VERSION "_"

NS_ :

BS_:

BU_: bms_lv dash dspace sens_front sens_rear tlb_bat

BO_ 20 BMSLV_Helo : 8 bms_lv
	SG_ time : 0|64@1+ (1,0) [0|18446744073709552000] "" dspace

BO_ 21 Sens_Front_Helo : 8 bms_lv
	SG_ time : 0|64@1+ (1,0) [0|18446744073709552000] "" dspace

BO_ 22 Sens_Rear_Helo : 8 bms_lv
	SG_ time : 0|64@1+ (1,0) [0|18446744073709552000] "" dspace

BO_ 23 Steering_Helo : 8 bms_lv
	SG_ time : 0|64@1+ (1,0) [0|18446744073709552000] "" dspace

BO_ 24 TLB_Battery_Helo : 8 bms_lv
	SG_ time : 0|64@1+ (1,0) [0|18446744073709552000] "" dspace

BO_ 25 dSpaxe_Helo : 8 bms_lv
	SG_ time : 0|64@1+ (1,0) [0|18446744073709552000] "" dspace

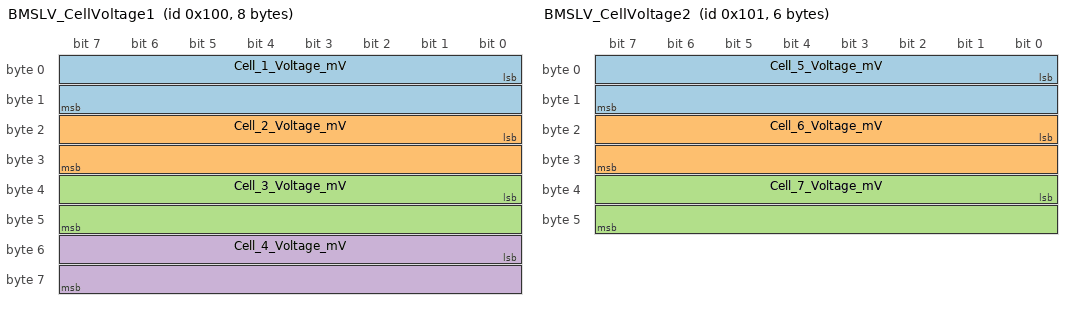
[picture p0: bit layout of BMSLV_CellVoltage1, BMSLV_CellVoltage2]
BO_ 256 BMSLV_CellVoltage1 : 8 bms_lv
	SG_ Cell_1_Voltage_mV : 0|16@1+ (0.038,2000) [0|2490.33] "" dspace
	SG_ Cell_2_Voltage_mV : 16|16@1+ (0.038,2000) [0|2490.33] "" dspace
	SG_ Cell_3_Voltage_mV : 32|16@1+ (0.038,2000) [0|2490.33] "" dspace
	SG_ Cell_4_Voltage_mV : 48|16@1+ (0.038,2000) [0|2490.33] "" dspace

BO_ 257 BMSLV_CellVoltage2 : 6 bms_lv
	SG_ Cell_5_Voltage_mV : 0|16@1+ (0.038,2000) [0|2490.33] "" dspace
	SG_ Cell_6_Voltage_mV : 16|16@1+ (0.038,2000) [0|2490.33] "" dspace
	SG_ Cell_7_Voltage_mV : 32|16@1+ (0.038,2000) [0|2490.33] "" dspace

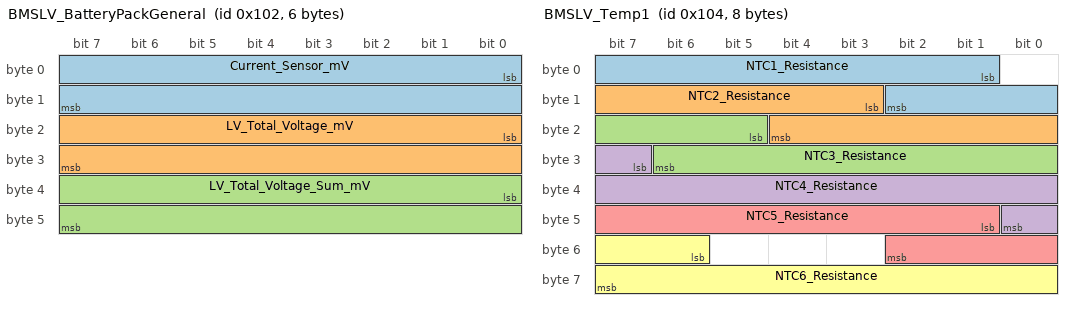
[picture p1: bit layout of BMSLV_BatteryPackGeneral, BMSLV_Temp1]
BO_ 258 BMSLV_BatteryPackGeneral : 6 bms_lv
	SG_ Current_Sensor_mV : 0|16@1+ (0.076,0) [0|4980.66] "" dspace
	SG_ LV_Total_Voltage_mV : 16|16@1+ (0.267,14000) [0|17497.845] "" dspace
	SG_ LV_Total_Voltage_Sum_mV : 32|16@1+ (0.267,14000) [0|17497.845] "" dspace

BO_ 259 BMSLV_Status : 4 bms_lv
	SG_ isRelayOpen : 0|1@1+ (1,0) [0|1] "" dspace
	SG_ cell1_OV : 1|1@1+ (1,0) [0|1] "" dspace
	SG_ cell2_OV : 2|1@1+ (1,0) [0|1] "" dspace
	SG_ cell3_OV : 3|1@1+ (1,0) [0|1] "" dspace
	SG_ cell4_OV : 4|1@1+ (1,0) [0|1] "" dspace
	SG_ cell5_OV : 5|1@1+ (1,0) [0|1] "" dspace
	SG_ cell6_OV : 6|1@1+ (1,0) [0|1] "" dspace
	SG_ cell7_OV : 7|1@1+ (1,0) [0|1] "" dspace
	SG_ cell1_UV : 8|1@1+ (1,0) [0|1] "" dspace
	SG_ cell2_UV : 9|1@1+ (1,0) [0|1] "" dspace
	SG_ cell3_UV : 10|1@1+ (1,0) [0|1] "" dspace
	SG_ cell4_UV : 11|1@1+ (1,0) [0|1] "" dspace
	SG_ cell5_UV : 12|1@1+ (1,0) [0|1] "" dspace
	SG_ cell6_UV : 13|1@1+ (1,0) [0|1] "" dspace
	SG_ cell7_UV : 14|1@1+ (1,0) [0|1] "" dspace
	SG_ temp1_OT : 15|1@1+ (1,0) [0|1] "" dspace
	SG_ temp2_OT : 16|1@1+ (1,0) [0|1] "" dspace
	SG_ temp3_OT : 17|1@1+ (1,0) [0|1] "" dspace
	SG_ temp4_OT : 18|1@1+ (1,0) [0|1] "" dspace
	SG_ temp5_OT : 19|1@1+ (1,0) [0|1] "" dspace
	SG_ temp6_OT : 20|1@1+ (1,0) [0|1] "" dspace
	SG_ temp7_OT : 21|1@1+ (1,0) [0|1] "" dspace
	SG_ temp8_OT : 22|1@1+ (1,0) [0|1] "" dspace
	SG_ temp9_OT : 23|1@1+ (1,0) [0|1] "" dspace
	SG_ temp10_OT : 24|1@1+ (1,0) [0|1] "" dspace
	SG_ temp11_OT : 25|1@1+ (1,0) [0|1] "" dspace
	SG_ temp12_OT : 26|1@1+ (1,0) [0|1] "" dspace

BO_ 260 BMSLV_Temp1 : 8 bms_lv
	SG_ NTC1_Resistance : 1|10@1+ (31.25,1000) [0|31968.75] "Ohm" dspace
	SG_ NTC2_Resistance : 11|10@1+ (31.25,1000) [0|31968.75] "Ohm" dspace
	SG_ NTC3_Resistance : 21|10@1+ (31.25,1000) [0|31968.75] "Ohm" dspace
	SG_ NTC4_Resistance : 31|10@1+ (31.25,1000) [0|31968.75] "Ohm" dspace
	SG_ NTC5_Resistance : 41|10@1+ (31.25,1000) [0|31968.75] "Ohm" dspace
	SG_ NTC6_Resistance : 54|10@1+ (31.25,1000) [0|31968.75] "Ohm" dspace

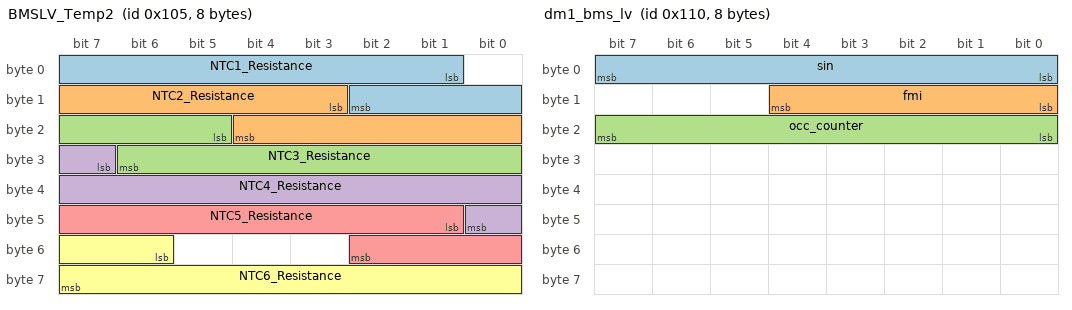
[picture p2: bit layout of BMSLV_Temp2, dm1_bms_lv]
BO_ 261 BMSLV_Temp2 : 8 bms_lv
	SG_ NTC1_Resistance : 1|10@1+ (31.25,1000) [0|31968.75] "Ohm" dspace
	SG_ NTC2_Resistance : 11|10@1+ (31.25,1000) [0|31968.75] "Ohm" dspace
	SG_ NTC3_Resistance : 21|10@1+ (31.25,1000) [0|31968.75] "Ohm" dspace
	SG_ NTC4_Resistance : 31|10@1+ (31.25,1000) [0|31968.75] "Ohm" dspace
	SG_ NTC5_Resistance : 41|10@1+ (31.25,1000) [0|31968.75] "Ohm" dspace
	SG_ NTC6_Resistance : 54|10@1+ (31.25,1000) [0|31968.75] "Ohm" dspace

BO_ 272 dm1_bms_lv : 8 bms_lv
	SG_ sin : 0|8@1+ (1,0) [0|117] "" Vector__XXX
	SG_ fmi : 8|5@1+ (1,0) [0|31] "" Vector__XXX
	SG_ occ_counter : 16|8@1+ (1,0) [0|255] "" Vector__XXX

BO_ 38 Steering_RTD : 1 dash
	SG_ RTD_CMD : 0|8@1+ (1,0) [0|255] "" dspace

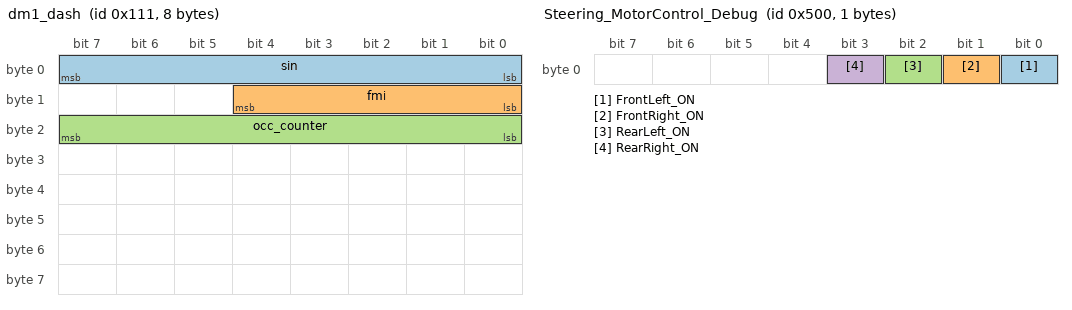
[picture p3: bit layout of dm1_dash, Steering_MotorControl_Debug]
BO_ 273 dm1_dash : 8 dash
	SG_ sin : 0|8@1+ (1,0) [0|117] "" Vector__XXX
	SG_ fmi : 8|5@1+ (1,0) [0|31] "" Vector__XXX
	SG_ occ_counter : 16|8@1+ (1,0) [0|255] "" Vector__XXX

BO_ 1280 Steering_MotorControl_Debug : 1 dash
	SG_ FrontLeft_ON : 0|1@1- (1,0) [0|1] "" dspace
	SG_ FrontRight_ON : 1|1@1- (1,0) [0|1] "" dspace
	SG_ RearLeft_ON : 2|1@1- (1,0) [0|1] "" dspace
	SG_ RearRight_ON : 3|1@1- (1,0) [0|1] "" dspace

BO_ 37 dSpace_RTD_ACK : 1 dspace
	SG_ RTD_FSM_STATE : 0|8@1- (1,0) [-1|6] "" dash

BO_ 255 BMSLV_RelayOverride : 2 dspace
	SG_ password : 0|15@1+ (1,0) [0|65535] "" bms_lv
	SG_ close_relay : 15|1@1+ (1,0) [0|1] "" bms_lv

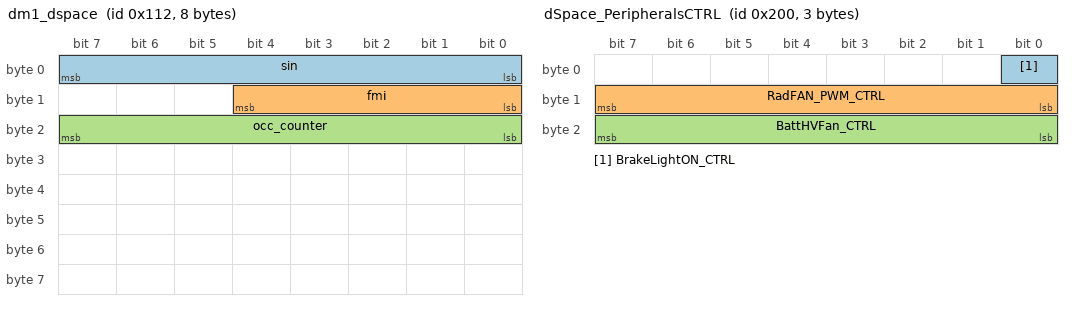
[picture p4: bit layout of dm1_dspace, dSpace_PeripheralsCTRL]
BO_ 274 dm1_dspace : 8 dspace
	SG_ sin : 0|8@1+ (1,0) [0|117] "" Vector__XXX
	SG_ fmi : 8|5@1+ (1,0) [0|31] "" Vector__XXX
	SG_ occ_counter : 16|8@1+ (1,0) [0|255] "" Vector__XXX

BO_ 512 dSpace_PeripheralsCTRL : 3 dspace
	SG_ BrakeLightON_CTRL : 0|1@1- (1,0) [0|1] "" dash
	SG_ RadFAN_PWM_CTRL : 8|8@1+ (1,0) [0|255] "" dash
	SG_ BattHVFan_CTRL : 16|8@1+ (1,0) [0|255] "" dash

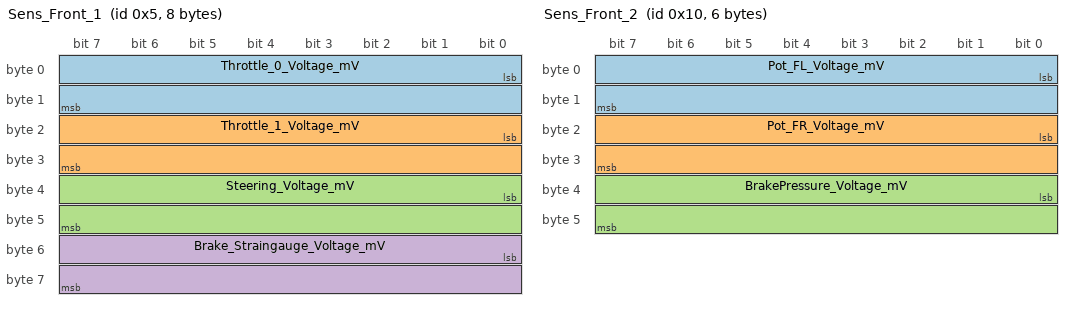
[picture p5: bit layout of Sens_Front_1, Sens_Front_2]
BO_ 5 Sens_Front_1 : 8 sens_front
	SG_ Throttle_0_Voltage_mV : 0|16@1+ (1,0) [0|65535] "" dspace
	SG_ Throttle_1_Voltage_mV : 16|16@1+ (1,0) [0|65535] "" dspace
	SG_ Steering_Voltage_mV : 32|16@1+ (1,0) [0|65535] "" dspace
	SG_ Brake_Straingauge_Voltage_mV : 48|16@1+ (1,0) [0|65535] "" dspace

BO_ 16 Sens_Front_2 : 6 sens_front
	SG_ Pot_FL_Voltage_mV : 0|16@1+ (1,0) [0|65535] "" dspace
	SG_ Pot_FR_Voltage_mV : 16|16@1+ (1,0) [0|65535] "" dspace
	SG_ BrakePressure_Voltage_mV : 32|16@1+ (1,0) [0|65535] "" dspace

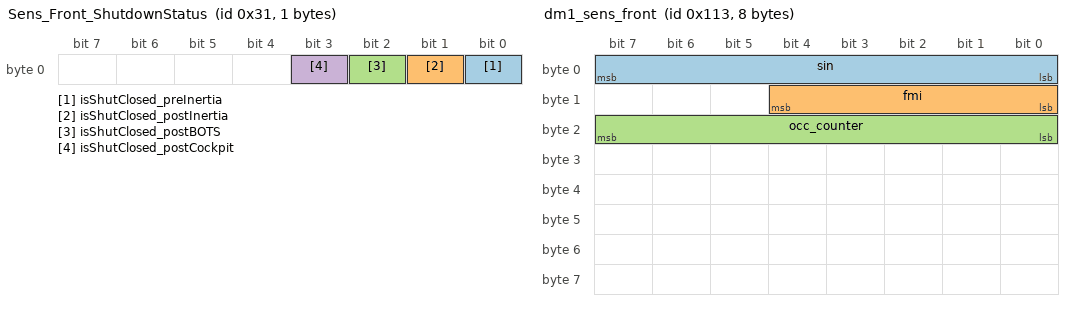
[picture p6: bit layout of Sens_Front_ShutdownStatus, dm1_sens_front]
BO_ 49 Sens_Front_ShutdownStatus : 1 sens_front
	SG_ isShutClosed_preInertia : 0|1@1- (1,0) [0|1] "" dspace
	SG_ isShutClosed_postInertia : 1|1@1- (1,0) [0|1] "" dspace
	SG_ isShutClosed_postBOTS : 2|1@1- (1,0) [0|1] "" dspace
	SG_ isShutClosed_postCockpit : 3|1@1- (1,0) [0|1] "" dspace

BO_ 275 dm1_sens_front : 8 sens_front
	SG_ sin : 0|8@1+ (1,0) [0|117] "" Vector__XXX
	SG_ fmi : 8|5@1+ (1,0) [0|31] "" Vector__XXX
	SG_ occ_counter : 16|8@1+ (1,0) [0|255] "" Vector__XXX

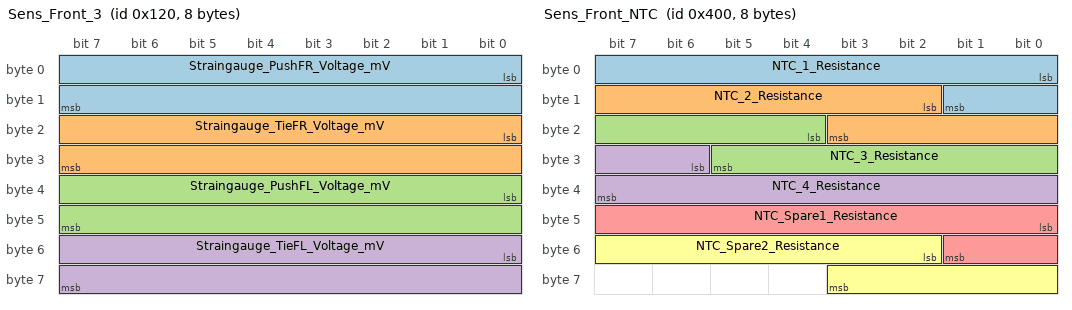
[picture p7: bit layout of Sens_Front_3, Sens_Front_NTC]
BO_ 288 Sens_Front_3 : 8 sens_front
	SG_ Straingauge_PushFR_Voltage_mV : 0|16@1+ (1,0) [0|65535] "" dspace
	SG_ Straingauge_TieFR_Voltage_mV : 16|16@1+ (1,0) [0|65535] "" dspace
	SG_ Straingauge_PushFL_Voltage_mV : 32|16@1+ (1,0) [0|65535] "" dspace
	SG_ Straingauge_TieFL_Voltage_mV : 48|16@1+ (1,0) [0|65535] "" dspace

BO_ 1024 Sens_Front_NTC : 8 sens_front
	SG_ NTC_1_Resistance : 0|10@1+ (31.25,1000) [0|31968.75] "Ohm" dspace
	SG_ NTC_2_Resistance : 10|10@1+ (31.25,1000) [0|31968.75] "Ohm" dspace
	SG_ NTC_3_Resistance : 20|10@1+ (31.25,1000) [0|31968.75] "Ohm" dspace
	SG_ NTC_4_Resistance : 30|10@1+ (31.25,1000) [0|31968.75] "Ohm" dspace
	SG_ NTC_Spare1_Resistance : 40|10@1+ (31.25,1000) [0|31968.75] "Ohm" dspace
	SG_ NTC_Spare2_Resistance : 50|10@1+ (31.25,1000) [0|31968.75] "Ohm" dspace

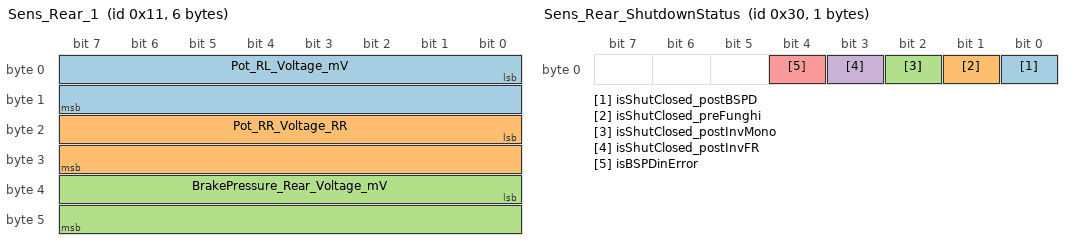
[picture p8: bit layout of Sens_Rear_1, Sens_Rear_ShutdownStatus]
BO_ 17 Sens_Rear_1 : 6 sens_rear
	SG_ Pot_RL_Voltage_mV : 0|16@1+ (1,0) [0|65535] "" dspace
	SG_ Pot_RR_Voltage_RR : 16|16@1+ (1,0) [0|65535] "" dspace
	SG_ BrakePressure_Rear_Voltage_mV : 32|16@1+ (1,0) [0|65535] "" dspace

BO_ 48 Sens_Rear_ShutdownStatus : 1 sens_rear
	SG_ isShutClosed_postBSPD : 0|1@1- (1,0) [0|1] "" dspace
	SG_ isShutClosed_preFunghi : 1|1@1- (1,0) [0|1] "" dspace
	SG_ isShutClosed_postInvMono : 2|1@1- (1,0) [0|1] "" dspace
	SG_ isShutClosed_postInvFR : 3|1@1- (1,0) [0|1] "" dspace
	SG_ isBSPDinError : 4|1@1- (1,0) [0|1] "" dspace

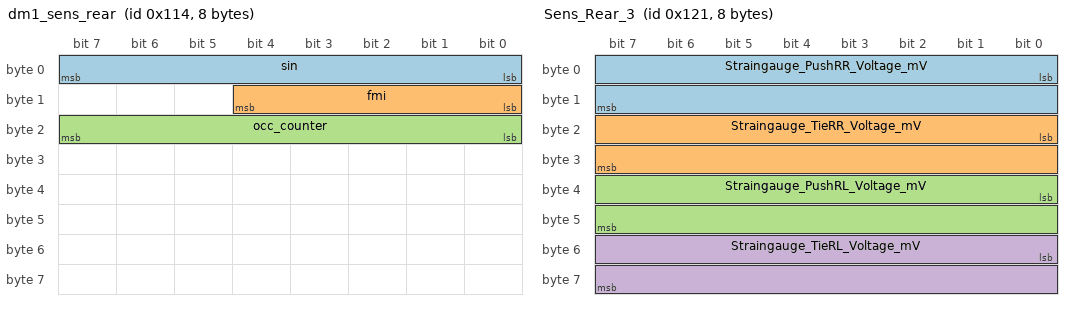
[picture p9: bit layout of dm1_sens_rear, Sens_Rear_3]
BO_ 276 dm1_sens_rear : 8 sens_rear
	SG_ sin : 0|8@1+ (1,0) [0|117] "" Vector__XXX
	SG_ fmi : 8|5@1+ (1,0) [0|31] "" Vector__XXX
	SG_ occ_counter : 16|8@1+ (1,0) [0|255] "" Vector__XXX

BO_ 289 Sens_Rear_3 : 8 sens_rear
	SG_ Straingauge_PushRR_Voltage_mV : 0|16@1+ (1,0) [0|65535] "" dspace
	SG_ Straingauge_TieRR_Voltage_mV : 16|16@1+ (1,0) [0|65535] "" dspace
	SG_ Straingauge_PushRL_Voltage_mV : 32|16@1+ (1,0) [0|65535] "" dspace
	SG_ Straingauge_TieRL_Voltage_mV : 48|16@1+ (1,0) [0|65535] "" dspace

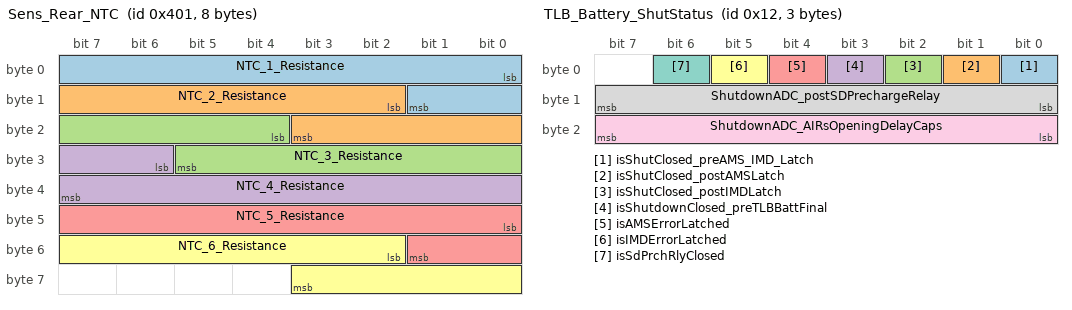
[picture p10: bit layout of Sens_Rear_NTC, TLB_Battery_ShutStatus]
BO_ 1025 Sens_Rear_NTC : 8 sens_rear
	SG_ NTC_1_Resistance : 0|10@1+ (31.25,1000) [0|31968.75] "Ohm" dspace
	SG_ NTC_2_Resistance : 10|10@1+ (31.25,1000) [0|31968.75] "Ohm" dspace
	SG_ NTC_3_Resistance : 20|10@1+ (31.25,1000) [0|31968.75] "Ohm" dspace
	SG_ NTC_4_Resistance : 30|10@1+ (31.25,1000) [0|31968.75] "Ohm" dspace
	SG_ NTC_5_Resistance : 40|10@1+ (31.25,1000) [0|31968.75] "Ohm" dspace
	SG_ NTC_6_Resistance : 50|10@1+ (31.25,1000) [0|31968.75] "Ohm" dspace

BO_ 1026 Sens_Rear_2 : 4 sens_rear
	SG_ CoolingPressure_DX_Voltage_mV : 0|16@1+ (1,0) [0|65535] "" dspace
	SG_ CoolingPressure_SX_Voltage_mV : 16|16@1+ (1,0) [0|65535] "" dspace

BO_ 18 TLB_Battery_ShutStatus : 3 tlb_bat
	SG_ isShutClosed_preAMS_IMD_Latch : 0|1@1+ (1,0) [0|1] "" dspace
	SG_ isShutClosed_postAMSLatch : 1|1@1+ (1,0) [0|1] "" dspace
	SG_ isShutClosed_postIMDLatch : 2|1@1+ (1,0) [0|1] "" dspace
	SG_ isShutdownClosed_preTLBBattFinal : 3|1@1+ (1,0) [0|1] "" dspace
	SG_ isAMSErrorLatched : 4|1@1+ (1,0) [0|1] "" dspace
	SG_ isIMDErrorLatched : 5|1@1+ (1,0) [0|1] "" dspace
	SG_ isSdPrchRlyClosed : 6|1@1+ (1,0) [0|1] "" dspace
	SG_ ShutdownADC_postSDPrechargeRelay : 8|8@1+ (0.117,0) [0|255] "V" dspace
	SG_ ShutdownADC_AIRsOpeningDelayCaps : 16|8@1+ (0.117,0) [0|255] "V" dspace

BO_ 19 TLB_Battery_TSALStatus : 3 tlb_bat
	SG_ TSAL_isGreenON : 0|1@1+ (1,0) [0|1] "" dspace
	SG_ TSAL_isAIRPosClosed : 1|1@1+ (1,0) [0|1] "" dspace
	SG_ TSAL_IsAIRNegClosed : 2|1@1+ (1,0) [0|1] "" dspace
	SG_ TSAL_IsRelayPrechargeClosed : 3|1@1+ (1,0) [0|1] "" dspace
	SG_ TSAL_isDCBusOver60V : 4|1@1+ (1,0) [0|1] "" dspace
	SG_ IntentionalState_AIRPos : 5|1@1+ (1,0) [0|1] "" dspace
	SG_ IntentionalState_AIRNeg : 6|1@1+ (1,0) [0|1] "" dspace
	SG_ IntentionalState_RelayPrecharge : 7|1@1+ (1,0) [0|1] "" dspace
	SG_ SCS_Short2GND_AirPos : 8|1@1+ (1,0) [0|1] "" dspace
	SG_ SCS_Short2GND_AirNeg : 9|1@1+ (1,0) [0|1] "" dspace
	SG_ SCS_isAnyShort2GND_Present : 10|1@1+ (1,0) [0|1] "" dspace
	SG_ Imp_isAnyImp_Present : 11|1@1+ (1,0) [0|1] "" dspace
	SG_ Imp_isAIRPosImp_Present : 12|1@1+ (1,0) [0|1] "" dspace
	SG_ Imp_isAIRNegImp_Present : 13|1@1+ (1,0) [0|1] "" dspace
	SG_ Imp_isRelayPrechargeImp_Present : 14|1@1+ (1,0) [0|1] "" dspace
	SG_ Imp_isDCBusVoltageImp_Present : 15|1@1+ (1,0) [0|1] "" dspace
	SG_ Imp_isAnyImp_Latched : 16|1@1+ (1,0) [0|1] "" dspace

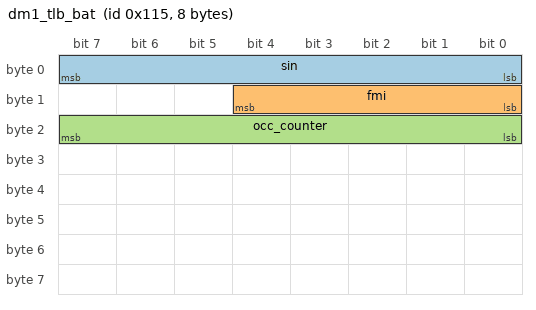
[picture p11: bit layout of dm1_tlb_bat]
BO_ 277 dm1_tlb_bat : 8 tlb_bat
	SG_ sin : 0|8@1+ (1,0) [0|117] "" Vector__XXX
	SG_ fmi : 8|5@1+ (1,0) [0|31] "" Vector__XXX
	SG_ occ_counter : 16|8@1+ (1,0) [0|255] "" Vector__XXX

CM_ BU_ bms_lv "battery-management-system low-voltage";
CM_ BO_ 22 "(period: 10 ms)";
CM_ BO_ 256 "(period: 100 ms)";
CM_ BO_ 257 "(period: 100 ms)";
CM_ BO_ 258 "(period: 100 ms)";
CM_ BO_ 259 "(period: 100 ms)";
CM_ BO_ 260 "(period: 2000 ms)";
CM_ BO_ 261 "(period: 2000 ms)";
CM_ BU_ dash "dashboard ECU";
CM_ BO_ 38 "(period: 500 ms)";
CM_ BU_ dspace "automotive ECU";
CM_ BU_ sens_front "sensorboard front ECU";
CM_ BO_ 5 "(period: 10 ms)";
CM_ BO_ 16 "(period: 10 ms)";
CM_ BO_ 49 "(period: 10 ms)";
CM_ BO_ 288 "(period: 10 ms)";
CM_ BO_ 1024 "(period: 10 ms)";
CM_ BU_ sens_rear "sensorboard rear ECU";
CM_ BO_ 17 "(period: 10 ms)";
CM_ BO_ 48 "(period: 10 ms)";
CM_ BO_ 289 "(period: 10 ms)";
CM_ BO_ 1025 "(period: 10 ms)";
CM_ BO_ 1026 "(period: 10 ms)";
CM_ BU_ tlb_bat "tsal-latch-board battery ECU";
CM_ BO_ 18 "(period: 100 ms)";
CM_ BO_ 19 "(period: 100 ms)";

VAL_ 272 sin 0 "time" 1 "Cell_1_Voltage_mV" 2 "Cell_2_Voltage_mV" 3 "Cell_3_Voltage_mV" 4 "Cell_4_Voltage_mV" 5 "Cell_5_Voltage_mV" 6 "Cell_6_Voltage_mV" 7 "Cell_7_Voltage_mV" 8 "Current_Sensor_mV" 9 "LV_Total_Voltage_mV" 10 "LV_Total_Voltage_Sum_mV" 11 "isRelayOpen" 12 "cell1_OV" 13 "cell2_OV" 14 "cell3_OV" 15 "cell4_OV" 16 "cell5_OV" 17 "cell6_OV" 18 "cell7_OV" 19 "cell1_UV" 20 "cell2_UV" 21 "cell3_UV" 22 "cell4_UV" 23 "cell5_UV" 24 "cell6_UV" 25 "cell7_UV" 26 "temp1_OT" 27 "temp2_OT" 28 "temp3_OT" 29 "temp4_OT" 30 "temp5_OT" 31 "temp6_OT" 32 "temp7_OT" 33 "temp8_OT" 34 "temp9_OT" 35 "temp10_OT" 36 "temp11_OT" 37 "temp12_OT" 38 "NTC1_Resistance" 39 "NTC2_Resistance" 40 "NTC3_Resistance" 41 "NTC4_Resistance" 42 "NTC5_Resistance" 43 "NTC6_Resistance" 44 "RTD_CMD" 45 "FrontLeft_ON" 46 "FrontRight_ON" 47 "RearLeft_ON" 48 "RearRight_ON" 49 "RTD_FSM_STATE" 50 "password" 51 "close_relay" 52 "BrakeLightON_CTRL" 53 "RadFAN_PWM_CTRL" 54 "BattHVFan_CTRL" 55 "Throttle_0_Voltage_mV" 56 "Throttle_1_Voltage_mV" 57 "Steering_Voltage_mV" 58 "Brake_Straingauge_Voltage_mV" 59 "Pot_FL_Voltage_mV" 60 "Pot_FR_Voltage_mV" 61 "BrakePressure_Voltage_mV" 62 "isShutClosed_preInertia" 63 "isShutClosed_postInertia" 64 "isShutClosed_postBOTS" 65 "isShutClosed_postCockpit" 66 "Straingauge_PushFR_Voltage_mV" 67 "Straingauge_TieFR_Voltage_mV" 68 "Straingauge_PushFL_Voltage_mV" 69 "Straingauge_TieFL_Voltage_mV" 70 "NTC_1_Resistance" 71 "NTC_2_Resistance" 72 "NTC_3_Resistance" 73 "NTC_4_Resistance" 74 "NTC_Spare1_Resistance" 75 "NTC_Spare2_Resistance" 76 "Pot_RL_Voltage_mV" 77 "Pot_RR_Voltage_RR" 78 "BrakePressure_Rear_Voltage_mV" 79 "isShutClosed_postBSPD" 80 "isShutClosed_preFunghi" 81 "isShutClosed_postInvMono" 82 "isShutClosed_postInvFR" 83 "isBSPDinError" 84 "Straingauge_PushRR_Voltage_mV" 85 "Straingauge_TieRR_Voltage_mV" 86 "Straingauge_PushRL_Voltage_mV" 87 "Straingauge_TieRL_Voltage_mV" 88 "NTC_5_Resistance" 89 "NTC_6_Resistance" 90 "CoolingPressure_DX_Voltage_mV" 91 "CoolingPressure_SX_Voltage_mV" 92 "isShutClosed_preAMS_IMD_Latch" 93 "isShutClosed_postAMSLatch" 94 "isShutClosed_postIMDLatch" 95 "isShutdownClosed_preTLBBattFinal" 96 "isAMSErrorLatched" 97 "isIMDErrorLatched" 98 "isSdPrchRlyClosed" 99 "ShutdownADC_postSDPrechargeRelay" 100 "ShutdownADC_AIRsOpeningDelayCaps" 101 "TSAL_isGreenON" 102 "TSAL_isAIRPosClosed" 103 "TSAL_IsAIRNegClosed" 104 "TSAL_IsRelayPrechargeClosed" 105 "TSAL_isDCBusOver60V" 106 "IntentionalState_AIRPos" 107 "IntentionalState_AIRNeg" 108 "IntentionalState_RelayPrecharge" 109 "SCS_Short2GND_AirPos" 110 "SCS_Short2GND_AirNeg" 111 "SCS_isAnyShort2GND_Present" 112 "Imp_isAnyImp_Present" 113 "Imp_isAIRPosImp_Present" 114 "Imp_isAIRNegImp_Present" 115 "Imp_isRelayPrechargeImp_Present" 116 "Imp_isDCBusVoltageImp_Present" 117 "Imp_isAnyImp_Latched";
VAL_ 272 fmi 0 "high_severity" 1 "low_severity" 2 "erratic" 3 "v_above_normal" 4 "v_below_normal" 5 "i_above_normal" 6 "i_below_normal" 7 "system_not_responding_properly" 8 "abnormal_frequency" 9 "abnormal_update_rate" 10 "abnormal_rate_of_change" 11 "other_failure_mode" 12 "failure" 13 "out_of_calibration" 14 "special_instruction" 15 "data_valid_above_normal_range0" 16 "data_valid_above_normal_range1" 17 "data_valid_below_normal_range0" 18 "data_valid_below_normal_range1" 19 "received_network_data_error" 20 "data_drifted_high" 21 "data_drifted_low" 31 "condition_exists";
VAL_ 273 sin 0 "time" 1 "Cell_1_Voltage_mV" 2 "Cell_2_Voltage_mV" 3 "Cell_3_Voltage_mV" 4 "Cell_4_Voltage_mV" 5 "Cell_5_Voltage_mV" 6 "Cell_6_Voltage_mV" 7 "Cell_7_Voltage_mV" 8 "Current_Sensor_mV" 9 "LV_Total_Voltage_mV" 10 "LV_Total_Voltage_Sum_mV" 11 "isRelayOpen" 12 "cell1_OV" 13 "cell2_OV" 14 "cell3_OV" 15 "cell4_OV" 16 "cell5_OV" 17 "cell6_OV" 18 "cell7_OV" 19 "cell1_UV" 20 "cell2_UV" 21 "cell3_UV" 22 "cell4_UV" 23 "cell5_UV" 24 "cell6_UV" 25 "cell7_UV" 26 "temp1_OT" 27 "temp2_OT" 28 "temp3_OT" 29 "temp4_OT" 30 "temp5_OT" 31 "temp6_OT" 32 "temp7_OT" 33 "temp8_OT" 34 "temp9_OT" 35 "temp10_OT" 36 "temp11_OT" 37 "temp12_OT" 38 "NTC1_Resistance" 39 "NTC2_Resistance" 40 "NTC3_Resistance" 41 "NTC4_Resistance" 42 "NTC5_Resistance" 43 "NTC6_Resistance" 44 "RTD_CMD" 45 "FrontLeft_ON" 46 "FrontRight_ON" 47 "RearLeft_ON" 48 "RearRight_ON" 49 "RTD_FSM_STATE" 50 "password" 51 "close_relay" 52 "BrakeLightON_CTRL" 53 "RadFAN_PWM_CTRL" 54 "BattHVFan_CTRL" 55 "Throttle_0_Voltage_mV" 56 "Throttle_1_Voltage_mV" 57 "Steering_Voltage_mV" 58 "Brake_Straingauge_Voltage_mV" 59 "Pot_FL_Voltage_mV" 60 "Pot_FR_Voltage_mV" 61 "BrakePressure_Voltage_mV" 62 "isShutClosed_preInertia" 63 "isShutClosed_postInertia" 64 "isShutClosed_postBOTS" 65 "isShutClosed_postCockpit" 66 "Straingauge_PushFR_Voltage_mV" 67 "Straingauge_TieFR_Voltage_mV" 68 "Straingauge_PushFL_Voltage_mV" 69 "Straingauge_TieFL_Voltage_mV" 70 "NTC_1_Resistance" 71 "NTC_2_Resistance" 72 "NTC_3_Resistance" 73 "NTC_4_Resistance" 74 "NTC_Spare1_Resistance" 75 "NTC_Spare2_Resistance" 76 "Pot_RL_Voltage_mV" 77 "Pot_RR_Voltage_RR" 78 "BrakePressure_Rear_Voltage_mV" 79 "isShutClosed_postBSPD" 80 "isShutClosed_preFunghi" 81 "isShutClosed_postInvMono" 82 "isShutClosed_postInvFR" 83 "isBSPDinError" 84 "Straingauge_PushRR_Voltage_mV" 85 "Straingauge_TieRR_Voltage_mV" 86 "Straingauge_PushRL_Voltage_mV" 87 "Straingauge_TieRL_Voltage_mV" 88 "NTC_5_Resistance" 89 "NTC_6_Resistance" 90 "CoolingPressure_DX_Voltage_mV" 91 "CoolingPressure_SX_Voltage_mV" 92 "isShutClosed_preAMS_IMD_Latch" 93 "isShutClosed_postAMSLatch" 94 "isShutClosed_postIMDLatch" 95 "isShutdownClosed_preTLBBattFinal" 96 "isAMSErrorLatched" 97 "isIMDErrorLatched" 98 "isSdPrchRlyClosed" 99 "ShutdownADC_postSDPrechargeRelay" 100 "ShutdownADC_AIRsOpeningDelayCaps" 101 "TSAL_isGreenON" 102 "TSAL_isAIRPosClosed" 103 "TSAL_IsAIRNegClosed" 104 "TSAL_IsRelayPrechargeClosed" 105 "TSAL_isDCBusOver60V" 106 "IntentionalState_AIRPos" 107 "IntentionalState_AIRNeg" 108 "IntentionalState_RelayPrecharge" 109 "SCS_Short2GND_AirPos" 110 "SCS_Short2GND_AirNeg" 111 "SCS_isAnyShort2GND_Present" 112 "Imp_isAnyImp_Present" 113 "Imp_isAIRPosImp_Present" 114 "Imp_isAIRNegImp_Present" 115 "Imp_isRelayPrechargeImp_Present" 116 "Imp_isDCBusVoltageImp_Present" 117 "Imp_isAnyImp_Latched";
VAL_ 273 fmi 0 "high_severity" 1 "low_severity" 2 "erratic" 3 "v_above_normal" 4 "v_below_normal" 5 "i_above_normal" 6 "i_below_normal" 7 "system_not_responding_properly" 8 "abnormal_frequency" 9 "abnormal_update_rate" 10 "abnormal_rate_of_change" 11 "other_failure_mode" 12 "failure" 13 "out_of_calibration" 14 "special_instruction" 15 "data_valid_above_normal_range0" 16 "data_valid_above_normal_range1" 17 "data_valid_below_normal_range0" 18 "data_valid_below_normal_range1" 19 "received_network_data_error" 20 "data_drifted_high" 21 "data_drifted_low" 31 "condition_exists";
VAL_ 274 sin 0 "time" 1 "Cell_1_Voltage_mV" 2 "Cell_2_Voltage_mV" 3 "Cell_3_Voltage_mV" 4 "Cell_4_Voltage_mV" 5 "Cell_5_Voltage_mV" 6 "Cell_6_Voltage_mV" 7 "Cell_7_Voltage_mV" 8 "Current_Sensor_mV" 9 "LV_Total_Voltage_mV" 10 "LV_Total_Voltage_Sum_mV" 11 "isRelayOpen" 12 "cell1_OV" 13 "cell2_OV" 14 "cell3_OV" 15 "cell4_OV" 16 "cell5_OV" 17 "cell6_OV" 18 "cell7_OV" 19 "cell1_UV" 20 "cell2_UV" 21 "cell3_UV" 22 "cell4_UV" 23 "cell5_UV" 24 "cell6_UV" 25 "cell7_UV" 26 "temp1_OT" 27 "temp2_OT" 28 "temp3_OT" 29 "temp4_OT" 30 "temp5_OT" 31 "temp6_OT" 32 "temp7_OT" 33 "temp8_OT" 34 "temp9_OT" 35 "temp10_OT" 36 "temp11_OT" 37 "temp12_OT" 38 "NTC1_Resistance" 39 "NTC2_Resistance" 40 "NTC3_Resistance" 41 "NTC4_Resistance" 42 "NTC5_Resistance" 43 "NTC6_Resistance" 44 "RTD_CMD" 45 "FrontLeft_ON" 46 "FrontRight_ON" 47 "RearLeft_ON" 48 "RearRight_ON" 49 "RTD_FSM_STATE" 50 "password" 51 "close_relay" 52 "BrakeLightON_CTRL" 53 "RadFAN_PWM_CTRL" 54 "BattHVFan_CTRL" 55 "Throttle_0_Voltage_mV" 56 "Throttle_1_Voltage_mV" 57 "Steering_Voltage_mV" 58 "Brake_Straingauge_Voltage_mV" 59 "Pot_FL_Voltage_mV" 60 "Pot_FR_Voltage_mV" 61 "BrakePressure_Voltage_mV" 62 "isShutClosed_preInertia" 63 "isShutClosed_postInertia" 64 "isShutClosed_postBOTS" 65 "isShutClosed_postCockpit" 66 "Straingauge_PushFR_Voltage_mV" 67 "Straingauge_TieFR_Voltage_mV" 68 "Straingauge_PushFL_Voltage_mV" 69 "Straingauge_TieFL_Voltage_mV" 70 "NTC_1_Resistance" 71 "NTC_2_Resistance" 72 "NTC_3_Resistance" 73 "NTC_4_Resistance" 74 "NTC_Spare1_Resistance" 75 "NTC_Spare2_Resistance" 76 "Pot_RL_Voltage_mV" 77 "Pot_RR_Voltage_RR" 78 "BrakePressure_Rear_Voltage_mV" 79 "isShutClosed_postBSPD" 80 "isShutClosed_preFunghi" 81 "isShutClosed_postInvMono" 82 "isShutClosed_postInvFR" 83 "isBSPDinError" 84 "Straingauge_PushRR_Voltage_mV" 85 "Straingauge_TieRR_Voltage_mV" 86 "Straingauge_PushRL_Voltage_mV" 87 "Straingauge_TieRL_Voltage_mV" 88 "NTC_5_Resistance" 89 "NTC_6_Resistance" 90 "CoolingPressure_DX_Voltage_mV" 91 "CoolingPressure_SX_Voltage_mV" 92 "isShutClosed_preAMS_IMD_Latch" 93 "isShutClosed_postAMSLatch" 94 "isShutClosed_postIMDLatch" 95 "isShutdownClosed_preTLBBattFinal" 96 "isAMSErrorLatched" 97 "isIMDErrorLatched" 98 "isSdPrchRlyClosed" 99 "ShutdownADC_postSDPrechargeRelay" 100 "ShutdownADC_AIRsOpeningDelayCaps" 101 "TSAL_isGreenON" 102 "TSAL_isAIRPosClosed" 103 "TSAL_IsAIRNegClosed" 104 "TSAL_IsRelayPrechargeClosed" 105 "TSAL_isDCBusOver60V" 106 "IntentionalState_AIRPos" 107 "IntentionalState_AIRNeg" 108 "IntentionalState_RelayPrecharge" 109 "SCS_Short2GND_AirPos" 110 "SCS_Short2GND_AirNeg" 111 "SCS_isAnyShort2GND_Present" 112 "Imp_isAnyImp_Present" 113 "Imp_isAIRPosImp_Present" 114 "Imp_isAIRNegImp_Present" 115 "Imp_isRelayPrechargeImp_Present" 116 "Imp_isDCBusVoltageImp_Present" 117 "Imp_isAnyImp_Latched";
VAL_ 274 fmi 0 "high_severity" 1 "low_severity" 2 "erratic" 3 "v_above_normal" 4 "v_below_normal" 5 "i_above_normal" 6 "i_below_normal" 7 "system_not_responding_properly" 8 "abnormal_frequency" 9 "abnormal_update_rate" 10 "abnormal_rate_of_change" 11 "other_failure_mode" 12 "failure" 13 "out_of_calibration" 14 "special_instruction" 15 "data_valid_above_normal_range0" 16 "data_valid_above_normal_range1" 17 "data_valid_below_normal_range0" 18 "data_valid_below_normal_range1" 19 "received_network_data_error" 20 "data_drifted_high" 21 "data_drifted_low" 31 "condition_exists";
VAL_ 275 sin 0 "time" 1 "Cell_1_Voltage_mV" 2 "Cell_2_Voltage_mV" 3 "Cell_3_Voltage_mV" 4 "Cell_4_Voltage_mV" 5 "Cell_5_Voltage_mV" 6 "Cell_6_Voltage_mV" 7 "Cell_7_Voltage_mV" 8 "Current_Sensor_mV" 9 "LV_Total_Voltage_mV" 10 "LV_Total_Voltage_Sum_mV" 11 "isRelayOpen" 12 "cell1_OV" 13 "cell2_OV" 14 "cell3_OV" 15 "cell4_OV" 16 "cell5_OV" 17 "cell6_OV" 18 "cell7_OV" 19 "cell1_UV" 20 "cell2_UV" 21 "cell3_UV" 22 "cell4_UV" 23 "cell5_UV" 24 "cell6_UV" 25 "cell7_UV" 26 "temp1_OT" 27 "temp2_OT" 28 "temp3_OT" 29 "temp4_OT" 30 "temp5_OT" 31 "temp6_OT" 32 "temp7_OT" 33 "temp8_OT" 34 "temp9_OT" 35 "temp10_OT" 36 "temp11_OT" 37 "temp12_OT" 38 "NTC1_Resistance" 39 "NTC2_Resistance" 40 "NTC3_Resistance" 41 "NTC4_Resistance" 42 "NTC5_Resistance" 43 "NTC6_Resistance" 44 "RTD_CMD" 45 "FrontLeft_ON" 46 "FrontRight_ON" 47 "RearLeft_ON" 48 "RearRight_ON" 49 "RTD_FSM_STATE" 50 "password" 51 "close_relay" 52 "BrakeLightON_CTRL" 53 "RadFAN_PWM_CTRL" 54 "BattHVFan_CTRL" 55 "Throttle_0_Voltage_mV" 56 "Throttle_1_Voltage_mV" 57 "Steering_Voltage_mV" 58 "Brake_Straingauge_Voltage_mV" 59 "Pot_FL_Voltage_mV" 60 "Pot_FR_Voltage_mV" 61 "BrakePressure_Voltage_mV" 62 "isShutClosed_preInertia" 63 "isShutClosed_postInertia" 64 "isShutClosed_postBOTS" 65 "isShutClosed_postCockpit" 66 "Straingauge_PushFR_Voltage_mV" 67 "Straingauge_TieFR_Voltage_mV" 68 "Straingauge_PushFL_Voltage_mV" 69 "Straingauge_TieFL_Voltage_mV" 70 "NTC_1_Resistance" 71 "NTC_2_Resistance" 72 "NTC_3_Resistance" 73 "NTC_4_Resistance" 74 "NTC_Spare1_Resistance" 75 "NTC_Spare2_Resistance" 76 "Pot_RL_Voltage_mV" 77 "Pot_RR_Voltage_RR" 78 "BrakePressure_Rear_Voltage_mV" 79 "isShutClosed_postBSPD" 80 "isShutClosed_preFunghi" 81 "isShutClosed_postInvMono" 82 "isShutClosed_postInvFR" 83 "isBSPDinError" 84 "Straingauge_PushRR_Voltage_mV" 85 "Straingauge_TieRR_Voltage_mV" 86 "Straingauge_PushRL_Voltage_mV" 87 "Straingauge_TieRL_Voltage_mV" 88 "NTC_5_Resistance" 89 "NTC_6_Resistance" 90 "CoolingPressure_DX_Voltage_mV" 91 "CoolingPressure_SX_Voltage_mV" 92 "isShutClosed_preAMS_IMD_Latch" 93 "isShutClosed_postAMSLatch" 94 "isShutClosed_postIMDLatch" 95 "isShutdownClosed_preTLBBattFinal" 96 "isAMSErrorLatched" 97 "isIMDErrorLatched" 98 "isSdPrchRlyClosed" 99 "ShutdownADC_postSDPrechargeRelay" 100 "ShutdownADC_AIRsOpeningDelayCaps" 101 "TSAL_isGreenON" 102 "TSAL_isAIRPosClosed" 103 "TSAL_IsAIRNegClosed" 104 "TSAL_IsRelayPrechargeClosed" 105 "TSAL_isDCBusOver60V" 106 "IntentionalState_AIRPos" 107 "IntentionalState_AIRNeg" 108 "IntentionalState_RelayPrecharge" 109 "SCS_Short2GND_AirPos" 110 "SCS_Short2GND_AirNeg" 111 "SCS_isAnyShort2GND_Present" 112 "Imp_isAnyImp_Present" 113 "Imp_isAIRPosImp_Present" 114 "Imp_isAIRNegImp_Present" 115 "Imp_isRelayPrechargeImp_Present" 116 "Imp_isDCBusVoltageImp_Present" 117 "Imp_isAnyImp_Latched";
VAL_ 275 fmi 0 "high_severity" 1 "low_severity" 2 "erratic" 3 "v_above_normal" 4 "v_below_normal" 5 "i_above_normal" 6 "i_below_normal" 7 "system_not_responding_properly" 8 "abnormal_frequency" 9 "abnormal_update_rate" 10 "abnormal_rate_of_change" 11 "other_failure_mode" 12 "failure" 13 "out_of_calibration" 14 "special_instruction" 15 "data_valid_above_normal_range0" 16 "data_valid_above_normal_range1" 17 "data_valid_below_normal_range0" 18 "data_valid_below_normal_range1" 19 "received_network_data_error" 20 "data_drifted_high" 21 "data_drifted_low" 31 "condition_exists";
VAL_ 276 sin 0 "time" 1 "Cell_1_Voltage_mV" 2 "Cell_2_Voltage_mV" 3 "Cell_3_Voltage_mV" 4 "Cell_4_Voltage_mV" 5 "Cell_5_Voltage_mV" 6 "Cell_6_Voltage_mV" 7 "Cell_7_Voltage_mV" 8 "Current_Sensor_mV" 9 "LV_Total_Voltage_mV" 10 "LV_Total_Voltage_Sum_mV" 11 "isRelayOpen" 12 "cell1_OV" 13 "cell2_OV" 14 "cell3_OV" 15 "cell4_OV" 16 "cell5_OV" 17 "cell6_OV" 18 "cell7_OV" 19 "cell1_UV" 20 "cell2_UV" 21 "cell3_UV" 22 "cell4_UV" 23 "cell5_UV" 24 "cell6_UV" 25 "cell7_UV" 26 "temp1_OT" 27 "temp2_OT" 28 "temp3_OT" 29 "temp4_OT" 30 "temp5_OT" 31 "temp6_OT" 32 "temp7_OT" 33 "temp8_OT" 34 "temp9_OT" 35 "temp10_OT" 36 "temp11_OT" 37 "temp12_OT" 38 "NTC1_Resistance" 39 "NTC2_Resistance" 40 "NTC3_Resistance" 41 "NTC4_Resistance" 42 "NTC5_Resistance" 43 "NTC6_Resistance" 44 "RTD_CMD" 45 "FrontLeft_ON" 46 "FrontRight_ON" 47 "RearLeft_ON" 48 "RearRight_ON" 49 "RTD_FSM_STATE" 50 "password" 51 "close_relay" 52 "BrakeLightON_CTRL" 53 "RadFAN_PWM_CTRL" 54 "BattHVFan_CTRL" 55 "Throttle_0_Voltage_mV" 56 "Throttle_1_Voltage_mV" 57 "Steering_Voltage_mV" 58 "Brake_Straingauge_Voltage_mV" 59 "Pot_FL_Voltage_mV" 60 "Pot_FR_Voltage_mV" 61 "BrakePressure_Voltage_mV" 62 "isShutClosed_preInertia" 63 "isShutClosed_postInertia" 64 "isShutClosed_postBOTS" 65 "isShutClosed_postCockpit" 66 "Straingauge_PushFR_Voltage_mV" 67 "Straingauge_TieFR_Voltage_mV" 68 "Straingauge_PushFL_Voltage_mV" 69 "Straingauge_TieFL_Voltage_mV" 70 "NTC_1_Resistance" 71 "NTC_2_Resistance" 72 "NTC_3_Resistance" 73 "NTC_4_Resistance" 74 "NTC_Spare1_Resistance" 75 "NTC_Spare2_Resistance" 76 "Pot_RL_Voltage_mV" 77 "Pot_RR_Voltage_RR" 78 "BrakePressure_Rear_Voltage_mV" 79 "isShutClosed_postBSPD" 80 "isShutClosed_preFunghi" 81 "isShutClosed_postInvMono" 82 "isShutClosed_postInvFR" 83 "isBSPDinError" 84 "Straingauge_PushRR_Voltage_mV" 85 "Straingauge_TieRR_Voltage_mV" 86 "Straingauge_PushRL_Voltage_mV" 87 "Straingauge_TieRL_Voltage_mV" 88 "NTC_5_Resistance" 89 "NTC_6_Resistance" 90 "CoolingPressure_DX_Voltage_mV" 91 "CoolingPressure_SX_Voltage_mV" 92 "isShutClosed_preAMS_IMD_Latch" 93 "isShutClosed_postAMSLatch" 94 "isShutClosed_postIMDLatch" 95 "isShutdownClosed_preTLBBattFinal" 96 "isAMSErrorLatched" 97 "isIMDErrorLatched" 98 "isSdPrchRlyClosed" 99 "ShutdownADC_postSDPrechargeRelay" 100 "ShutdownADC_AIRsOpeningDelayCaps" 101 "TSAL_isGreenON" 102 "TSAL_isAIRPosClosed" 103 "TSAL_IsAIRNegClosed" 104 "TSAL_IsRelayPrechargeClosed" 105 "TSAL_isDCBusOver60V" 106 "IntentionalState_AIRPos" 107 "IntentionalState_AIRNeg" 108 "IntentionalState_RelayPrecharge" 109 "SCS_Short2GND_AirPos" 110 "SCS_Short2GND_AirNeg" 111 "SCS_isAnyShort2GND_Present" 112 "Imp_isAnyImp_Present" 113 "Imp_isAIRPosImp_Present" 114 "Imp_isAIRNegImp_Present" 115 "Imp_isRelayPrechargeImp_Present" 116 "Imp_isDCBusVoltageImp_Present" 117 "Imp_isAnyImp_Latched";
VAL_ 276 fmi 0 "high_severity" 1 "low_severity" 2 "erratic" 3 "v_above_normal" 4 "v_below_normal" 5 "i_above_normal" 6 "i_below_normal" 7 "system_not_responding_properly" 8 "abnormal_frequency" 9 "abnormal_update_rate" 10 "abnormal_rate_of_change" 11 "other_failure_mode" 12 "failure" 13 "out_of_calibration" 14 "special_instruction" 15 "data_valid_above_normal_range0" 16 "data_valid_above_normal_range1" 17 "data_valid_below_normal_range0" 18 "data_valid_below_normal_range1" 19 "received_network_data_error" 20 "data_drifted_high" 21 "data_drifted_low" 31 "condition_exists";
VAL_ 277 sin 0 "time" 1 "Cell_1_Voltage_mV" 2 "Cell_2_Voltage_mV" 3 "Cell_3_Voltage_mV" 4 "Cell_4_Voltage_mV" 5 "Cell_5_Voltage_mV" 6 "Cell_6_Voltage_mV" 7 "Cell_7_Voltage_mV" 8 "Current_Sensor_mV" 9 "LV_Total_Voltage_mV" 10 "LV_Total_Voltage_Sum_mV" 11 "isRelayOpen" 12 "cell1_OV" 13 "cell2_OV" 14 "cell3_OV" 15 "cell4_OV" 16 "cell5_OV" 17 "cell6_OV" 18 "cell7_OV" 19 "cell1_UV" 20 "cell2_UV" 21 "cell3_UV" 22 "cell4_UV" 23 "cell5_UV" 24 "cell6_UV" 25 "cell7_UV" 26 "temp1_OT" 27 "temp2_OT" 28 "temp3_OT" 29 "temp4_OT" 30 "temp5_OT" 31 "temp6_OT" 32 "temp7_OT" 33 "temp8_OT" 34 "temp9_OT" 35 "temp10_OT" 36 "temp11_OT" 37 "temp12_OT" 38 "NTC1_Resistance" 39 "NTC2_Resistance" 40 "NTC3_Resistance" 41 "NTC4_Resistance" 42 "NTC5_Resistance" 43 "NTC6_Resistance" 44 "RTD_CMD" 45 "FrontLeft_ON" 46 "FrontRight_ON" 47 "RearLeft_ON" 48 "RearRight_ON" 49 "RTD_FSM_STATE" 50 "password" 51 "close_relay" 52 "BrakeLightON_CTRL" 53 "RadFAN_PWM_CTRL" 54 "BattHVFan_CTRL" 55 "Throttle_0_Voltage_mV" 56 "Throttle_1_Voltage_mV" 57 "Steering_Voltage_mV" 58 "Brake_Straingauge_Voltage_mV" 59 "Pot_FL_Voltage_mV" 60 "Pot_FR_Voltage_mV" 61 "BrakePressure_Voltage_mV" 62 "isShutClosed_preInertia" 63 "isShutClosed_postInertia" 64 "isShutClosed_postBOTS" 65 "isShutClosed_postCockpit" 66 "Straingauge_PushFR_Voltage_mV" 67 "Straingauge_TieFR_Voltage_mV" 68 "Straingauge_PushFL_Voltage_mV" 69 "Straingauge_TieFL_Voltage_mV" 70 "NTC_1_Resistance" 71 "NTC_2_Resistance" 72 "NTC_3_Resistance" 73 "NTC_4_Resistance" 74 "NTC_Spare1_Resistance" 75 "NTC_Spare2_Resistance" 76 "Pot_RL_Voltage_mV" 77 "Pot_RR_Voltage_RR" 78 "BrakePressure_Rear_Voltage_mV" 79 "isShutClosed_postBSPD" 80 "isShutClosed_preFunghi" 81 "isShutClosed_postInvMono" 82 "isShutClosed_postInvFR" 83 "isBSPDinError" 84 "Straingauge_PushRR_Voltage_mV" 85 "Straingauge_TieRR_Voltage_mV" 86 "Straingauge_PushRL_Voltage_mV" 87 "Straingauge_TieRL_Voltage_mV" 88 "NTC_5_Resistance" 89 "NTC_6_Resistance" 90 "CoolingPressure_DX_Voltage_mV" 91 "CoolingPressure_SX_Voltage_mV" 92 "isShutClosed_preAMS_IMD_Latch" 93 "isShutClosed_postAMSLatch" 94 "isShutClosed_postIMDLatch" 95 "isShutdownClosed_preTLBBattFinal" 96 "isAMSErrorLatched" 97 "isIMDErrorLatched" 98 "isSdPrchRlyClosed" 99 "ShutdownADC_postSDPrechargeRelay" 100 "ShutdownADC_AIRsOpeningDelayCaps" 101 "TSAL_isGreenON" 102 "TSAL_isAIRPosClosed" 103 "TSAL_IsAIRNegClosed" 104 "TSAL_IsRelayPrechargeClosed" 105 "TSAL_isDCBusOver60V" 106 "IntentionalState_AIRPos" 107 "IntentionalState_AIRNeg" 108 "IntentionalState_RelayPrecharge" 109 "SCS_Short2GND_AirPos" 110 "SCS_Short2GND_AirNeg" 111 "SCS_isAnyShort2GND_Present" 112 "Imp_isAnyImp_Present" 113 "Imp_isAIRPosImp_Present" 114 "Imp_isAIRNegImp_Present" 115 "Imp_isRelayPrechargeImp_Present" 116 "Imp_isDCBusVoltageImp_Present" 117 "Imp_isAnyImp_Latched";
VAL_ 277 fmi 0 "high_severity" 1 "low_severity" 2 "erratic" 3 "v_above_normal" 4 "v_below_normal" 5 "i_above_normal" 6 "i_below_normal" 7 "system_not_responding_properly" 8 "abnormal_frequency" 9 "abnormal_update_rate" 10 "abnormal_rate_of_change" 11 "other_failure_mode" 12 "failure" 13 "out_of_calibration" 14 "special_instruction" 15 "data_valid_above_normal_range0" 16 "data_valid_above_normal_range1" 17 "data_valid_below_normal_range0" 18 "data_valid_below_normal_range1" 19 "received_network_data_error" 20 "data_drifted_high" 21 "data_drifted_low" 31 "condition_exists";
